# MM32L3xx register map
Vendor: MindMotion Ltd.; Series: MM32L3; File version: 1.4
MindMotion 32-bit Cortex-M3 Microcontroller based device, CPU clock up to 96 MHz, etc.
CPU: CM3 r1p1, little endian, no MPU, no FPU, 4 interrupt priority bits
Registers are 32-bit, read-write, reset 0x0 unless marked. A register's access mark holds for its fields unless they carry their own. Offsets are from the block's base; lines under a group give offsets from that group; [hi:lo] are bit positions; {n}, {i} and the like mark numbered series; 'fields as' and 'values as' point back to an identical list; <NAME> marks a mode.

## Memory map
0x40000000 TIM2 size 0x400 — General purpose timer
0x40000400 TIM3 size 0x400
0x40000800 TIM4 size 0x400
0x40002800 RTC size 0x400 — Real time clock
0x40002C00 WWDG size 0x400 — Window watchdog
0x40003000 IWDG size 0x400 — Independent watchdog
0x40003800 SPI2 size 0x400
0x40004400 UART2 size 0x400
0x40004800 UART3 size 0x400
0x40005400 I2C1 size 0x400 — Inter integrated circuit
0x40005800 I2C2 size 0x400
0x40005C00 USB size 0x400 — Universal serial bus full-speed device interface
0x40006400 CAN size 0x400 — Controller area network
0x40006C00 BKP size 0x400 — Backup registers
0x40007000 PWR size 0x400 — Power control
0x40007400 DAC size 0x400 — Digital to analog converter
0x40010000 AFIO size 0x400 — Alternate function I/O
0x40010400 EXTI size 0x400
0x40010800 GPIOA size 0x400 — General purpose I/O
0x40010C00 GPIOB size 0x400
0x40011000 GPIOC size 0x400
0x40011400 GPIOD size 0x400
0x40011800 GPIOE size 0x400
0x40012400 ADC1 size 0x400 — Analog to digital converter
0x40012800 ADC2 size 0x400 — Analog to digital converter
0x40012C00 TIM1 size 0x400 — Advanced timer
0x40013000 SPI1 size 0x400 — Serial peripheral interface
0x40013800 UART1 size 0x400 — Universal asynchronous receiver transmitter
0x40020000 DMA size 0x400 — DMA controller
0x40021000 RCC size 0x400 — Reset and clock control
0x40022000 FLASH size 0x400
0x40023000 CRC size 0x400 — CRC calculation unit
0xE0042000 DBG size 0x400 — Debug support

## Interrupts
0 WWDG — Window Watchdog interrupt
1 PVD (PWR) — PVD through EXTI line detection interrupt
2 TAMPER (EXTI) — Tamper interrupt
3 RTC — RTC global interrupt
4 FLASH — Flash global interrupt
5 RCC — RCC global interrupt
6 EXTI0 (EXTI) — EXTI Line0 interrupt
7 EXTI1 (EXTI) — EXTI Line1 interrupt
8 EXTI2 (EXTI) — EXTI Line2 interrupt
9 EXTI3 (EXTI) — EXTI Line3 interrupt
10 EXTI4 (EXTI) — EXTI Line4 interrupt
11 DMA_Channel1 (DMA) — DMA Channel1 global interrupt
12 DMA_Channel2 (DMA) — DMA Channel2 global interrupt
13 DMA_Channel3 (DMA) — DMA Channel3 global interrupt
14 DMA_Channel4 (DMA) — DMA Channel4 global interrupt
15 DMA_Channel5 (DMA) — DMA Channel5 global interrupt
16 DMA_Channel6 (DMA) — DMA Channel6 global interrupt
17 DMA_Channel7 (DMA) — DMA Channel7 global interrupt
18 ADC (ADC1, ADC2) — ADC1 global interrupt
21 CAN_RX1 (CAN) — CAN RX1 interrupts
23 EXTI9_5 (EXTI) — EXTI Line[9:5] interrupts
27 TIM1_CC (TIM1) — TIM1 Capture Compare interrupt
28 TIM2 — TIM2 global interrupt
29 TIM3 — TIM3 global interrupt
30 TIM4 — TIM4 global interrupt
31 I2C1_EV (I2C1) — I2C1 event interrupt
33 I2C2_EV (I2C2) — I2C2 event interrupt
35 SPI1 — SPI1 global interrupt
36 SPI2 — SPI2 global interrupt
37 UART1 — UART1 global interrupt
38 UART2 — UART2 global interrupt
39 UART3 — UART3 global interrupt
40 EXTI15_10 (EXTI) — EXTI Line[15:10] interrupts
41 RTCAlarm (RTC) — RTC Alarms through EXTI line interrupt
42 USB_FS_WKUP (USB) — USB Device FS Wakeup through EXTI line interrupt

## FLASH
Base 0x40022000
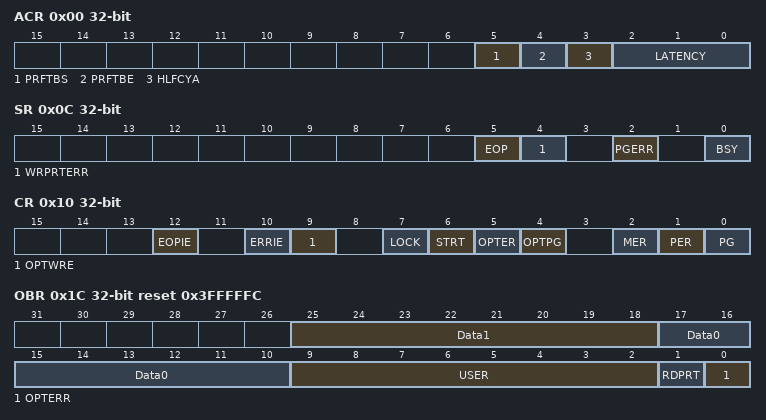
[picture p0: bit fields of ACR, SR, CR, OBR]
0x00 ACR
  [5] PRFTBS — Prefetch buffer status
  [4] PRFTBE — Prefetch buffer enable
  [3] HLFCYA — Flash half cycle access enable
  [2:0] LATENCY
0x04 KEYR wo
  [31:0] FKEYR — Flash key
0x08 OPTKEYR wo
  [31:0] OPTKEYR — Option byte key
0x0C SR
  [5] EOP — End of operation
  [4] WRPRTERR — Write protection error
  [2] PGERR — Programming error
  [0] BSY — Busy
0x10 CR
  [12] EOPIE — End of operation interrupt enable
  [10] ERRIE — Error interrupt enable
  [9] OPTWRE — Option byte write enable
  [7] LOCK
  [6] STRT — Start
  [5] OPTER — Option byte erase
  [4] OPTPG — Option byte programming
  [2] MER — Mass erase
  [1] PER — Page erase
  [0] PG — Programming
0x14 AR wo
  [31:0] FAR — Flash Address
0x1C OBR ro reset 0x3FFFFFC
  [25:18] Data1
  [17:10] Data0
  [9:2] USER — User option bytes
  [1] RDPRT — Read protection level status
  [0] OPTERR — Option byte error
0x20 WRPR ro reset 0xFFFFFFFF
  [31:0] WRP — Write protect

## Licence text in the file
MindMotion Limited (MindMotion) is supplying this software for use with Cortex-M3!
